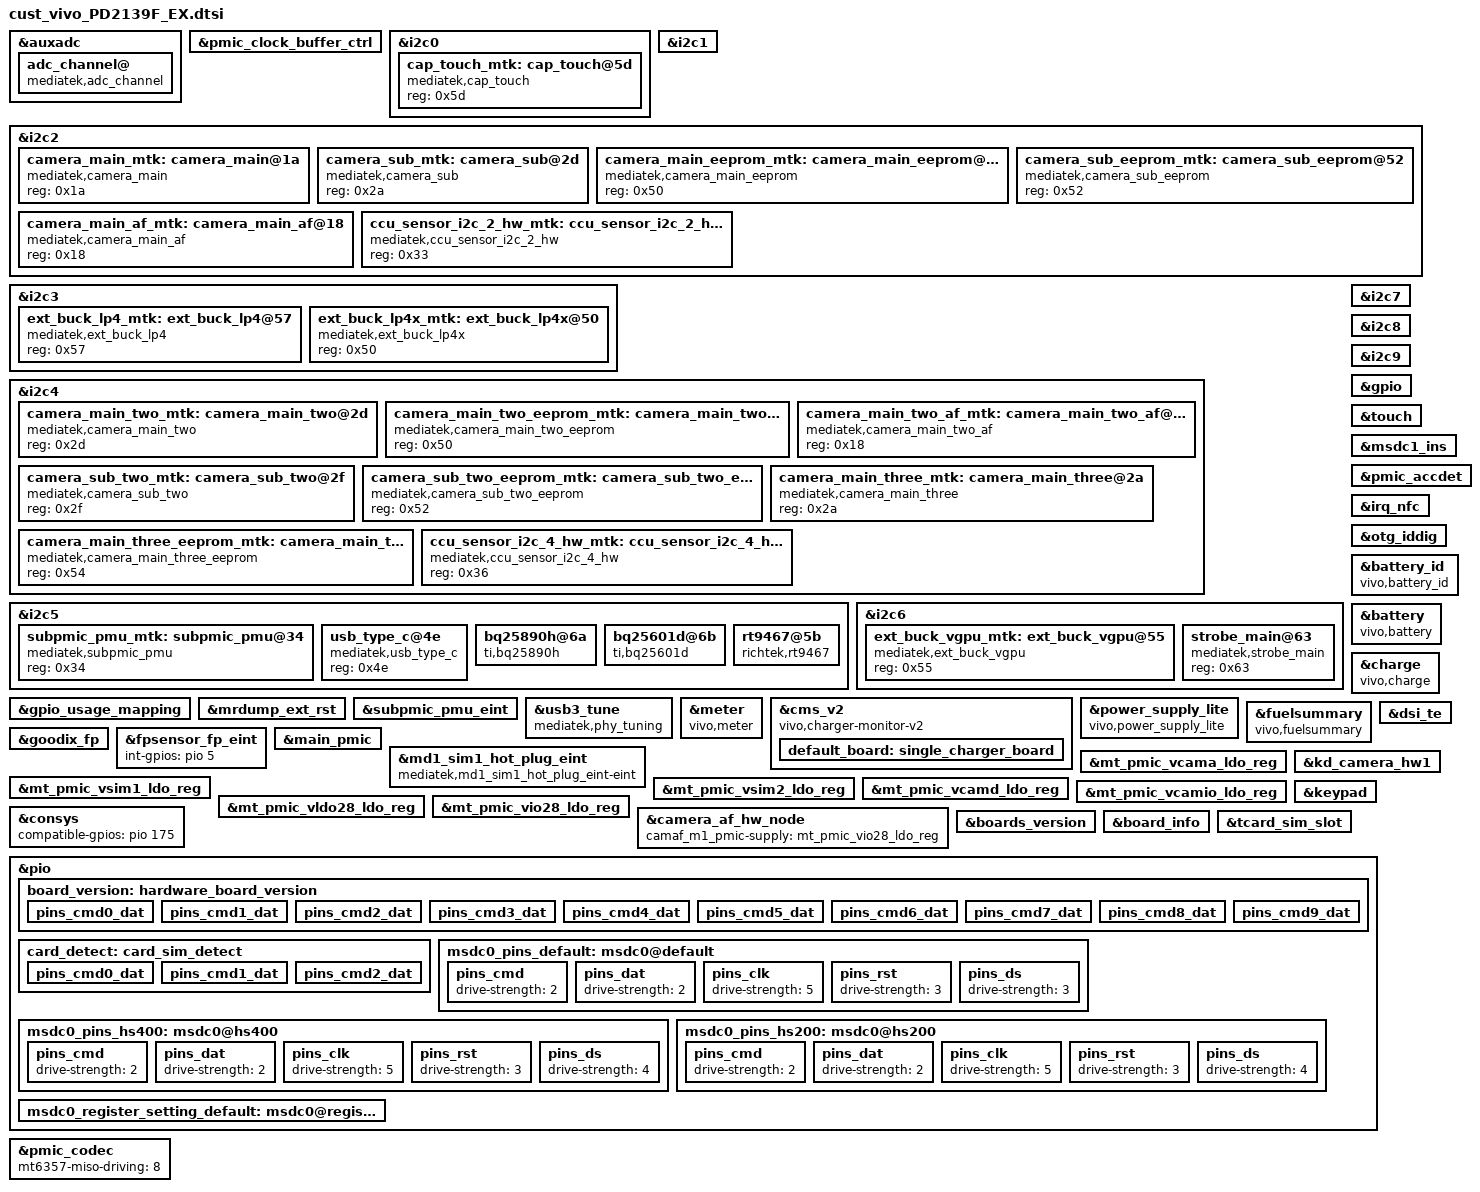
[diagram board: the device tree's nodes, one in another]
/*
 * Generated by MTK SP DrvGen Version: 3.5.160809 for MT6765.
 * 2018-01-30 14:59:45
 * Do Not Modify The File.
 * Copyright Mediatek Inc. (c) 2016.
*/

/*************************
 * ADC DTSI File
*************************/

&auxadc {
	adc_channel@ {
		compatible = "mediatek,adc_channel";
		mediatek,temperature0 = <0>;
		mediatek,temperature1 = <1>;
		mediatek,adc_fdd_rf_params_dynamic_custom_ch = <2>;
		status = "okay";
	};
};


/*************************
 * CLK_BUF DTSI File
*************************/

&pmic_clock_buffer_ctrl {
	mediatek,clkbuf-quantity = <7>;
	mediatek,clkbuf-config = <2 1 2 2 0 0 0>;
	mediatek,clkbuf-driving-current = <1 1 1 1 1 1 1>;
	status = "okay";
};


/*************************
 * I2C DTSI File
*************************/

&i2c0 {
	#address-cells = <1>;
	#size-cells = <0>;
	clock-frequency = <400000>;
	mediatek,use-open-drain;
	cap_touch_mtk:cap_touch@5d {
		compatible = "mediatek,cap_touch";
		reg = <0x5d>;
		status = "okay";
	};

};

&i2c1 {
	#address-cells = <1>;
	#size-cells = <0>;
	clock-frequency = <400000>;
	mediatek,use-open-drain;
};

&i2c2 {
	#address-cells = <1>;
	#size-cells = <0>;
	clock-frequency = <400000>;
	mediatek,use-open-drain;
	camera_main_mtk:camera_main@1a {
		compatible = "mediatek,camera_main";
		reg = <0x1a>;
		status = "okay";
	};

	camera_sub_mtk:camera_sub@2d {
		compatible = "mediatek,camera_sub";
		reg = <0x2a>;
		status = "okay";
	};

	camera_main_eeprom_mtk:camera_main_eeprom@50 {
		compatible = "mediatek,camera_main_eeprom";
		reg = <0x50>;
		status = "okay";
	};
        camera_sub_eeprom_mtk:camera_sub_eeprom@52 {
		compatible = "mediatek,camera_sub_eeprom";
		reg = <0x52>;
		status = "okay";
	};
	camera_main_af_mtk:camera_main_af@18 {
		compatible = "mediatek,camera_main_af";
		reg = <0x18>;
		status = "okay";
	};
	ccu_sensor_i2c_2_hw_mtk:ccu_sensor_i2c_2_hw@33 {
		compatible = "mediatek,ccu_sensor_i2c_2_hw";
		reg = <0x33>;
		status = "okay";
	};

};

&i2c3 {
	#address-cells = <1>;
	#size-cells = <0>;
	clock-frequency = <400000>;
	mediatek,use-open-drain;
	ext_buck_lp4_mtk:ext_buck_lp4@57 {
		compatible = "mediatek,ext_buck_lp4";
		reg = <0x57>;
		status = "okay";
	};

	ext_buck_lp4x_mtk:ext_buck_lp4x@50 {
		compatible = "mediatek,ext_buck_lp4x";
		reg = <0x50>;
		status = "okay";
	};

};

&i2c4 {
	#address-cells = <1>;
	#size-cells = <0>;
	clock-frequency = <400000>;
	mediatek,use-open-drain;
	camera_main_two_mtk:camera_main_two@2d {
		compatible = "mediatek,camera_main_two";
		reg = <0x2d>;
		status = "okay";
	};
	
	camera_main_two_eeprom_mtk:camera_main_two_eeprom@50 {
		compatible = "mediatek,camera_main_two_eeprom";
		reg = <0x50>;
		status = "okay";
	};

	camera_main_two_af_mtk:camera_main_two_af@18 {
		compatible = "mediatek,camera_main_two_af";
		reg = <0x18>;
		status = "okay";
	};
	camera_sub_two_mtk:camera_sub_two@2f {
		compatible = "mediatek,camera_sub_two";
		reg = <0x2f>;
		status = "okay";
	};
	camera_sub_two_eeprom_mtk:camera_sub_two_eeprom@52 {
		compatible = "mediatek,camera_sub_two_eeprom";
		reg = <0x52>;
		status = "okay";
	};
	camera_main_three_mtk:camera_main_three@2a {
		compatible = "mediatek,camera_main_three";
		reg = <0x2a>;
		status = "okay";
	};
	camera_main_three_eeprom_mtk:camera_main_three_eeprom@54 {
		compatible = "mediatek,camera_main_three_eeprom";
		reg = <0x54>;
		status = "okay";
	};
	ccu_sensor_i2c_4_hw_mtk:ccu_sensor_i2c_4_hw@36 {
		compatible = "mediatek,ccu_sensor_i2c_4_hw";
		reg = <0x36>;
		status = "okay";
	};
};

&i2c5 {
	#address-cells = <1>;
	#size-cells = <0>;
	clock-frequency = <400000>;
	mediatek,use-open-drain;
	subpmic_pmu_mtk:subpmic_pmu@34 {
		compatible = "mediatek,subpmic_pmu";
		reg = <0x34>;
		status = "okay";
	};
	usb_type_c@4e {
		compatible = "mediatek,usb_type_c";
		reg = <0x4e>;
		status = "okay";
	};
};

&i2c6 {
	#address-cells = <1>;
	#size-cells = <0>;
	clock-frequency = <400000>;
	mediatek,use-open-drain;

	ext_buck_vgpu_mtk:ext_buck_vgpu@55 {
		compatible = "mediatek,ext_buck_vgpu";
		reg = <0x55>;
		status = "okay";
	};

	/*hope add for flashlight i2c device start*/
	strobe_main@63 {
	        compatible = "mediatek,strobe_main";
	        reg = <0x63>;
	        status = "okay";
	};
	/*hope add for flashlight i2c device end*/

};

&i2c7 {
	#address-cells = <1>;
	#size-cells = <0>;
	clock-frequency = <400000>;
	mediatek,use-open-drain;
};

&i2c8 {
	#address-cells = <1>;
	#size-cells = <0>;
	clock-frequency = <400000>;
	mediatek,use-open-drain;
};

&i2c9 {
	#address-cells = <1>;
	#size-cells = <0>;
	clock-frequency = <400000>;
	mediatek,use-open-drain;
};



/*************************
 * GPIO DTSI File
*************************/

&gpio_usage_mapping {
	GPIO_SIM2_SIO = <&pio 35 0>;
	GPIO_SIM2_SRST = <&pio 36 0>;
	GPIO_SIM2_SCLK = <&pio 37 0>;
	GPIO_SIM1_SCLK = <&pio 38 0>;
	GPIO_SIM1_SRST = <&pio 39 0>;
	GPIO_SIM1_SIO = <&pio 40 0>;
	GPIO_SIM1_HOT_PLUG = <&pio 47 0>;
	GPIO_FDD_BAND_SUPPORT_DETECT_1ST_PIN = <&pio 176 0>;
	GPIO_FDD_BAND_SUPPORT_DETECT_2ND_PIN = <&pio 177 0>;
	GPIO_FDD_BAND_SUPPORT_DETECT_3RD_PIN = <&pio 178 0>;
	GPIO_FDD_BAND_SUPPORT_DETECT_4TH_PIN = <&pio 173 0>;
};

&gpio{
	gpio_init_default = <0 0 0 0 0 1 1>,
		<1 0 0 0 0 0 1>,
		<2 0 1 0 0 0 0>,//usb sel
		<3 0 0 0 1 1 1>,
		<4 0 0 0 1 1 0>,
		<5 0 0 0 1 0 0>,
		<6 0 0 0 1 1 0>,
		<7 0 0 0 1 1 0>,
		<8 0 0 0 0 0 1>,
		<9 0 0 0 0 0 0>,
		<10 0 1 0 1 1 1>,
		<11 0 0 0 0 0 0>,//main chg-int
		<12 0 0 0 1 0 0>,
		<13 3 0 0 1 0 0>,
		<14 3 1 0 0 0 0>,
		<15 3 1 0 0 0 0>,
		<16 3 1 0 0 0 0>,
		<17 2 0 0 1 0 0>,
		<18 2 0 0 1 0 0>,
		<19 2 0 0 0 0 0>,
		<20 2 0 0 1 0 0>,
		<21 0 1 0 0 0 0>,
		<22 0 0 0 1 0 0>,
		<23 0 0 0 0 0 0>,//sub chg-int
		<24 0 0 0 1 0 0>,
		<25 1 0 0 0 0 0>,
		<26 1 1 0 0 0 0>,
		<27 1 1 0 0 0 0>,
		<28 1 1 0 0 0 0>,
		<29 1 1 0 0 0 1>,
		<30 1 0 0 1 1 1>,
		<31 1 0 0 1 1 1>,
		<32 1 0 0 1 1 1>,
		<33 1 0 0 1 1 1>,
		<34 1 0 0 1 1 1>,
		<35 1 0 0 1 1 0>,
		<36 1 1 0 0 0 0>,
		<37 1 1 0 0 0 0>,
		<38 1 1 0 0 0 0>,
		<39 1 1 0 0 0 0>,
		<40 1 0 0 1 1 0>,
		<41 0 0 0 0 0 0>,
		<42 0 0 0 1 0 0>,
		<43 1 1 0 0 0 0>,
		<44 1 0 0 1 0 0>,
		<45 0 1 0 0 0 0>,
		<46 0 0 0 0 0 0>,
		<47 1 0 0 0 0 0>,
		<48 1 0 0 1 1 1>,
		<49 1 0 0 1 1 1>,
		<50 1 0 0 1 1 1>,
		<51 1 1 0 1 1 1>,
		<52 1 1 0 1 0 0>,
		<53 1 1 0 1 0 0>,
		<54 0 0 0 1 1 0>,
		<55 1 1 0 1 0 0>,
		<56 1 1 0 1 0 0>,
		<57 1 1 0 1 0 0>,
		<58 0 0 0 1 0 0>,
		<59 1 0 0 1 0 0>,
		<60 1 0 0 1 0 0>,
		<61 1 0 0 1 0 0>,
		<62 1 0 0 1 0 0>,
		<63 1 0 0 1 0 0>,
		<64 1 0 0 1 0 0>,
		<65 1 0 0 1 0 0>,
		<66 1 0 0 1 0 0>,
		<67 1 0 0 1 0 0>,
		<68 1 0 0 1 0 0>,
		<69 0 1 0 1 0 0>,//sub chg enable
		<70 1 1 0 1 0 0>,
		<71 1 1 0 1 0 0>,
		<72 1 1 0 1 0 0>,
		<73 0 1 0 1 0 0>,
		<74 0 1 0 1 0 0>,
		<75 0 0 0 1 0 0>,
		<76 1 1 0 1 0 0>,
		<77 1 1 0 1 0 0>,
		<78 0 0 0 1 1 0>,
		<79 0 0 0 1 0 0>,
		<80 0 0 0 1 0 0>,
		<81 1 0 0 1 1 1>,
		<82 1 0 0 1 1 1>,
		<83 1 0 0 1 1 1>,
		<84 1 0 0 1 1 1>,
		<85 1 1 0 1 0 0>,
		<86 1 1 0 1 0 0>,
		<87 0 1 0 0 0 0>,//CCM3_RST  front
		<88 0 0 0 1 0 0>,
		<89 1 0 0 1 0 0>,
		<90 0 0 0 1 0 0>,
		<91 0 1 0 1 0 0>,
		<92 0 0 0 1 0 0>,
		<93 1 0 0 1 1 0>,
		<94 0 0 0 1 0 0>,
		<95 1 0 0 1 1 0>,
		<96 1 1 0 0 0 0>,
		<97 0 1 0 0 0 0>,
		<98 0 1 0 0 0 0>,
		<99 0 1 0 0 0 0>,
		<100 0 1 0 0 0 0>,
		<101 0 1 0 0 0 0>,//ccm0_rst  rear main
		<102 0 1 0 0 0 0>,//cam2_rst  micro
		<103 1 0 0 0 0 1>,//iic2 scl
		<104 1 0 0 0 0 1>,//iic2 sda
		<105 1 0 0 0 0 1>,//iic4 scl
		<106 1 0 0 0 0 1>,//iic4 sda
		<107 0 0 0 1 1 0>,
		<108 0 1 0 0 0 0>,
		<109 0 1 0 0 0 0>,//CCM1_RST  boked
		<110 0 0 0 1 1 0>,//cc logic int-gpio
		<111 0 0 0 1 0 0>,
		<112 0 0 0 1 0 0>,
		<113 0 1 0 0 0 0>,
		<114 0 0 0 1 0 0>,
		<115 0 0 0 1 0 0>,
		<116 0 0 0 1 0 0>,
		<117 0 0 0 1 0 0>,
		<118 0 0 0 1 0 0>,
		<119 0 0 0 1 0 0>,
		<120 0 0 0 1 0 0>,
		<121 0 0 0 0 0 0>,
		<122 1 0 0 1 1 1>,
		<123 1 0 0 1 1 1>,
		<124 1 1 0 0 0 1>,
		<125 1 0 0 1 1 1>,
		<126 1 0 0 1 1 1>,
		<127 1 0 0 1 1 1>,
		<128 1 0 0 1 1 1>,
		<129 1 0 0 1 1 1>,
		<130 1 0 0 1 1 1>,
		<131 1 0 0 1 0 1>,
		<132 1 0 0 1 1 1>,
		<133 1 1 1 0 0 1>,
		<134 1 0 0 1 0 1>,
		<135 1 1 0 0 0 0>,
		<136 1 1 0 0 0 0>,
		<137 1 1 0 0 0 0>,
		<138 1 1 0 0 0 0>,
		<139 1 1 0 0 0 0>,
		<140 1 0 0 1 0 0>,
		<141 1 0 0 1 0 0>,
		<142 1 0 0 1 0 0>,
		<143 1 0 0 1 0 0>,
		<144 1 0 0 1 0 0>,
		<145 1 1 1 0 0 0>,
		<146 1 0 0 1 0 0>,
		<147 1 1 0 0 0 0>,
		<148 1 1 0 0 0 0>,
		<149 1 1 0 0 0 0>,
		<150 0 1 0 1 1 1>,
		<151 0 1 0 0 0 0>,
		<152 0 1 0 0 0 0>,
		<153 0 1 0 0 0 0>,
		<154 0 1 0 0 0 0>,
		<155 0 1 0 1 0 0>,
		<156 0 1 0 0 0 0>,
		<157 1 0 0 1 0 0>,
		<158 1 0 0 1 0 0>,
		<159 0 1 1 0 0 0>,
		<160 0 0 0 1 0 0>,
		<161 1 0 0 1 1 1>,
		<162 1 0 0 1 1 1>,
		<163 0 1 0 0 0 0>,//usb oe
		<164 0 0 0 0 0 0>,
		<165 0 0 0 0 0 0>,
		<166 0 1 0 1 0 0>,
		<167 0 0 0 1 0 0>,
		<168 0 0 0 1 0 0>,
		<169 0 1 0 0 0 0>,
		<170 0 1 0 0 0 0>,
		<171 0 0 0 1 1 0>,
		<172 0 1 1 0 0 0>,
		<173 0 0 0 1 1 0>,
		<174 0 0 0 1 1 0>,
		<175 0 0 0 1 1 0>,
		<176 0 0 0 1 1 0>,
		<177 0 0 0 1 1 0>,
		<178 0 0 0 1 1 0>,
		<179 0 0 0 1 0 0>;
};


/*************************
 * EINT DTSI File
*************************/

#include <dt-bindings/interrupt-controller/irq.h>
#include <dt-bindings/interrupt-controller/arm-gic.h>

&touch {
	interrupt-parent = <&pio>;
	interrupts = <0 IRQ_TYPE_EDGE_FALLING 0 0>;
	status = "okay";
};

&msdc1_ins {
	interrupt-parent = <&pio>;
	interrupts = <1 IRQ_TYPE_EDGE_FALLING 1 0>;
	status = "okay";
};

&mrdump_ext_rst {
	interrupt-parent = <&pio>;
	interrupts = <2 IRQ_TYPE_LEVEL_LOW 2 0>;
	deb-gpios = <&pio 2 0>;
	debounce = <512000>;
	status = "okay";
};

&pmic_accdet {
	interrupt-parent = <&pio>;
	interrupts = <4 IRQ_TYPE_LEVEL_LOW>,
				 <3 IRQ_TYPE_LEVEL_LOW>;
	deb-gpios = <&pio 4 0>;
	deb-rgpios = <&pio 3 0>;
	debounce = <256000>;
	debounce1 = <256000>;
	status = "okay";
};

&irq_nfc {
	interrupt-parent = <&pio>;
	interrupts = <10 IRQ_TYPE_LEVEL_HIGH 10 0>;
	status = "okay";
};

&subpmic_pmu_eint {
	interrupt-parent = <&pio>;
	interrupts = <11 IRQ_TYPE_EDGE_FALLING 11 0>;
	status = "okay";
};

&otg_iddig {
    interrupt-parent = <&pio>;
    interrupts = <110 IRQ_TYPE_LEVEL_LOW 110 0>;
    /*debounce = <110 0>;*/
    usbid-num = <&pio 110 1>;
	mtk,otg_chip_compatible_mode;
    usbid2-num = <&pio 167 1>;
    platform-id = <&pio 171 1>;
    pinctrl-names = "iddig_default", "iddig_otg_gpio", "iddig_otg_gpio_pull_down", "otg_gpio_pull_high", "otg_gpio_pull_low", "otg_gpio_pull_in", "otg_gpio_pull1_high", "otg_gpio_pull1_low", "otg_gpio_pull1_in", "iddig_otg_init", "otg_gpio167_pull_high", "otg_gpio167_pull_low", "otg_gpio167_pull_in";
    pinctrl-0 = <&iddig_default>;
    pinctrl-1 = <&gpio110_mode0_gpio>;
    pinctrl-2 = <&gpio110_mode0_gpio_pull_down>;
    pinctrl-3 = <&gpio165_otg_pull_high>;
    pinctrl-4 = <&gpio165_otg_pull_low>;
    pinctrl-5 = <&gpio165_otg_pull_in>;
    pinctrl-6 = <&gpio164_otg_pull1_high>;
    pinctrl-7 = <&gpio164_otg_pull1_low>;
    pinctrl-8 = <&gpio164_otg_pull1_in>;
    pinctrl-9 = <&gpio110_mode1_iddig>;
	
    pinctrl-10 = <&gpio167_otg_pull1_high>;
    pinctrl-11 = <&gpio167_otg_pull1_low>;
    pinctrl-12 = <&gpio167_otg_pull1_in>;
    status = "okay";
};

/*taozongchen add for usb start */
&usb3_tune {
	compatible = "mediatek,phy_tuning";
	u2_vrt_ref = <0x4>;
	u2_term_ref = <0x3>;
	u2_hstx_srctrl = <0x4>;
	u2_enhance = <0x3>;
	u2_vrt_ref_host = <0x4>;
	u2_term_ref_host = <0x5>;
	u2_hstx_srctrl_host = <0x4>;
	u2_enhance_host = <0x2>;

	board1_version_bit = <7>;
	board1_version_active = <0>;
	u2_vrt_ref1 = <0x4>;
	u2_term_ref1 = <0x3>;
	u2_hstx_srctrl1 = <0x4>;
	u2_enhance1 = <0x3>;
	u2_vrt_ref_host1 = <0x4>;
	u2_term_ref_host1 = <0x2>;
	u2_hstx_srctrl_host1 = <0x4>;
	u2_enhance_host1 = <0x2>;
	status = "okay";
};
/* taozongchen add for usb end */

/* fuxi add for battery&charge start */
&battery_id {
	status = "okay";
	compatible = "vivo,battery_id";

	vivo,bat-adc-ctrl-gpio = <&pio 159 0>;

	io-channels = <&auxadc 3>;
	io-channel-names = "battery_id_adc";

	vivo,bat-name = "B-S2 ATL 5000","B-S1 LW 5000","B-S2 ATL 5000","B-S3 ATL 5000","UNKNOWN";
};

&battery {
	status = "okay";
	compatible = "vivo,battery";

	io-channels = <&auxadc 0>,
		<&auxadc 1>,
		<&auxadc 2>;
	io-channel-names = "primary_board_therm",
		"pa_therm",
		"parallel_board_therm";

	vivo,low-volt-threshold = <3400>;
	vivo,soft-rise-percent = <96>;
	vivo,soft-rise-cumulative = <3>;
	vivo,soft-rise-keep-cumulative = <10>;
	vivo,percnet-sync-delta = <8>;
	vivo,percnet-sync-cumulative = <9>;
	vivo,full-sync-cumulative = <3>;
	vivo,soft-term-percent = <99>;
	vivo,soft-term-cumulative = <30>;
};

&charge {
	status = "okay";
	compatible = "vivo,charge";

	vivo,chg-wdt-s = <40>;
	vivo,re-chg-voltage-mv = <100>;
	vivo,prechg-voltage-mv = <3000>;
	vivo,iprechg-current-ma = <300>;
	vivo,iterm-current-ma = <256>;
	vivo,vreg-voltage-mv = <4430>;
	vivo,vindpm-voltage-mv = <4500>;
	vivo,sys-voltage-min-mv= <3300>;
	vivo,boostv-voltage-mv = <5150>;
	vivo,boostv-ilimit-ma = <1300>;
	vivo,ovp-voltage-mv = <14000>;

	/*
	 * 0  auto detect charging
	 * 1  vivo-normal chargine
	 * 2  vivo-single engine charging
	 * 3  vivo-dual engine charging
	 * 4  vivo-flash charging
	*/
	vivo,charge-scheme = <0>;
	vivo,direct-charger-enable;

	/*
	 * SUPPORTED_ADAPTER_DEFAULT = 0,
	 * SUPPORTED_ADAPTER_VIVO_LV_DCHG_5V_4500MA = 1,
	 * SUPPORTED_ADAPTER_VIVO_HV_DCHG_10V_2250MA = 2,
	 * SUPPORTED_ADAPTER_QC20__9V_2000MA = 3,
	 * SUPPORTED_ADAPTER_VIVO_HV_DCHG_10V_4000MA = 4,
	 * SUPPORTED_ADAPTER_MAX,
	 */
	vivo,supported-adapter = <3>;

	//parameter for 9V2A
	vivo,primary-ichg-max-ma = <2240>;
	vivo,parallel-ichg-max-ma = <1680>;

	vivo,flashchg-spec-ma = <2000 3300 6000>;
	vivo,fastchg-spec-ma = <2000 2100 3800>;
	vivo,normalchg-spec-ma = <2000 1500 2300>;

	/* 0---PMIC; 1---CHGIC */
	vivo,vbus-detect-source = <0>;

	vivo,usboe-gpio = <&pio 163 0>;
	vivo,usbsel-gpio = <&pio 2 0>;

	/*ffc*/
	//vivo,ffc-enable;
	vivo,ffc-iterm-ma = <(-750)>;
	vivo,ffc-vreg-mv = <4500>;
	vivo,ffc-temperature-range = <150 450>;
	vivo,ffc-full-vbat-table-size = <3>;
	vivo,ffc-full-vbat-table = <4480 4490 4460>;
	vivo,ffc-full-ibat-table-size = <2>;
	vivo,ffc-full-ibat-table = <150 349 (-980)>,
		<350 449 (-1176)>;
};

&meter {
	status = "okay";
	compatible = "vivo,meter";

	vivo,load-capacity-delta-max = <60>;
	vivo,poweron-delta-capacity = <20>;
	vivo,poweron-low-capacity = <3>;
	vivo,volt-car-delta = <10>;
	vivo,car-volt-delta = <8>;
	vivo,meter-res-compesate = <10>;
	vivo,ocv-board-compesate = <0>;

	/* 0---AGING_UNSUPPORTED; 1---DRIVER_SUPPORTED; 2---USPACE_SUPPORTED */
	vivo,battery-aging-support = <2>;

	vivo,capacity-mAh = <4910>;
	/*COLD_CHG COLD_DISCHG NORMAL_CHG NORMAL_DISCHG*/
	vivo,car-tune-value = <1000 1005 1010 1000>,
		<1030 1005 1010 1000>,
		<1000 1005 1010 1000>,
		<1010 1000 1010 1000>,
		<1000 1000 1000 1000>,
		<1000 1000 1000 1000>;
	vivo,bats-qmax = <4260 4300 4616 4860 4870>,
		<3200 3850 4400 4590 4660>,
		<4260 4300 4616 4860 4870>,
		<3900 4181 4505 4548 4590>,
		<4500 4668 4762 4851 4821>,
		<4500 4668 4762 4851 4821>;

	/* car-tune adjust remap */
	vivo,car-tune-adjust-enable;
	vivo,car-tune-adjust-size = <3>;
	vivo,car-tune-adjust-table = <0 10 (330) 7>,
		<11 20 (-30) 8>,
		<21 100 (-30) 12>;

	#include "bat_setting/vivo_battery_table_pd2139.dtsi"
};

&cms_v2 {
	compatible = "vivo,charger-monitor-v2";
	status = "okay";

	default_board: single_charger_board {
		/*default board: keep in xxxxxx*/
		support-board-version = "xxxxxx";

		vivo,bat-det-method = <0>;//r:0, rc:1, eprom:2, ex-fg:3
		vivo,bat-id-gpio = <&pio 159 0>;
		
		/*
		CHG0__CHARGING_TECHNOLOGY_NONE = 0,
		CHG1__NORMAL_CHARGING,			//5V/2A normal charging
		CHG2__QC2_CHARGING,				//9V/2A	QC2.0 charging
		CHG3__LOW_VOLTAGE_DIRECT_CHARGING,		//5V/4.5A direct charging
		CHG4__SINGLE_IC_DIV2_CHARGING,		//single IC Div/2 charging
		CHG5__DUAL_IC_DIV2_CHARGING,			//Dual IC Div/2 charging
		CHG6__DUAL_IC_DUAL_BATTERY_DIV2_CHARGING,	//Dual IC Div/2 charging
		CHGX__CHARGING_TECHNOLOGY_MAX,
		*/
		vivo,charging-technology = <2>;
		//vivo,no-bat-warning;
		//vivo,no-chg-timeout;
		vivo,chg-timeout-mins = <900>;

		//high temperature charger current control enable
		vivo,htccc-enable;
		vivo,htccc-data = <46 55 4100000 100000>;

		//vivo,fbon-scale-enable;/*disable default*/
		vivo,fbon-scale-data = <2 100 100>;

		//vivo,switch-scale-enable;/*disable from rom4.0*/
		vivo,switch-scale-data = <75 53>;

		vivo,calling-scale-enable;
		vivo,calling-scale-data = <100 21>;/*ibat:3900 * 0.54 = 2106,more than 1500,not exit dchg*/
		vivo,calling-dchg-disable;

		vivo,weixin-calling-scale-enable;
		vivo,weixin-calling-scale-data = <100 112>;/*5000mA*/

		//vivo,fixed-scale-enable;
		vivo,fixed-scale-data = <120 3800 0>;/*dchg fixed time adjust the max ibat,disable default*/

		/*data processing : batt-temp*/
		vivo,dp-batt-temp-enable;
		vivo,dp-batt-temp-data = <100>;

		/* charging current for devices in exhibition mode */
		vivo,exhibition-mode-current-primary = <2048>;
		vivo,exhibition-mode-current-parallel = <0>;

		       /*default tc parameter*/
		       //single charger ibat scale base on temperature battery cell info:1C/1.2C 3960mah
		       /* tmin, tmax, data, volt1, data_ex1, volt2, data_ex2. */
		       vivo,normal-tc-row-col = <10 9>;
		       vivo,normal-tc-data = <550 8888 0 0 0 0 0 0 0>,
			       <450 549 50 0 0 0 0 0 0>,
			       <200 449 100 4200000 70 0 0 0 0>,
			       <150 199 100 4200000 70 0 0 0 0>,
			       <100 149 70 4200000 50 0 0 0 0>,
			       <50 99 50 4200000 30 0 0 0 0>,
			       <0 49 50 4200000 30 0 0 0 0>,
			       <(-8888) (-1) 0 0 0 0 0 0 0>,
			       <(-8888) (-1) 0 0 0 0 0 0 0>,
			       <(-8888) (-1) 0 0 0 0 0 0 0>;

		       /*flash tc parameter*/
		       vivo,flash-normal-tc-row-col = <10 9>;
		       vivo,flash-normal-tc-data = <550 8888 0 0 0 0 0 0 0>,
			       <450 549 50 0 0 0 0 0 0>,
			       <350 449 123 4430000 87 0 0 0 0>,
			       <200 349 123 4430000 87 0 0 0 0>,
			       <150 199 123 4300000 102 4430000 80 0 0>,
			       <100 149 100 0 0 0 0 0 0>,
			       <50 99 70 4200000 50 0 0 0 0>,
			       <0 49 70 4200000 50 0 0 0 0>,
			       <(-50) (-1) 0 0 0 0 0 0 0>,
			       <(-8888) (-51) 0 0 0 0 0 0 0>;

		/*adjust fastchg base on board temperature and fb off*/
		vivo,intell-charge-enable;
		vivo,parallel-temp-enable = <1 1>;//<x y> x:fb-on y:fb-off

		/* Flash charge fb-on intell param */
		vivo,primary-fbon-tc-row-col = <6 3>;
		vivo,primary-fbon-tc-data = <460 8888 1600>,
			<410 459 2600>,
			<400 409 3000>,
			<390 399 3300>,
			<371 389 3700>,
			<(-8888) 370 6000>;

		vivo,parallel-fbon-tc-row-col = <1 3>;
		vivo,parallel-fbon-tc-data = <(-8888) 8888 0>;

		/* Flash charge fb-off intell param */
		vivo,primary-fboff-tc-row-col = <6 3>;
		vivo,primary-fboff-tc-data = <450 8888 1800>,
			<390 449 3000>,
			<380 389 3400>,
			<376 379 3700>,
			<371 375 4100>,
			<(-8888) 370 6000>;
		vivo,parallel-fboff-tc-row-col = <1 3>;
		vivo,parallel-fboff-tc-data = <(-8888) 8888 0>;

		/* 9v Fast charge fb-on intell param */
		vivo,9v-primary-fbon-tc-row-col = <7 3>;
		vivo,9v-primary-fbon-tc-data = <490 8888 500>,
			<470 489 500>,
			<450 469 900>,
			<435 449 1040>,
			<410 434 1200>,
			<380 409 1300>,
			<(-8888) 379 1500>;
		vivo,9v-parallel-fbon-tc-row-col = <6 3>;
		vivo,9v-parallel-fbon-tc-data = <460 8888 500>,
			<440 459 850>,
			<420 439 1060>,
			<400 419 1150>,
			<380 399 1300>,
			<(-8888) 379 1500>;
		// second parallel parameter, for rt9467
		vivo,9v-2nd-parallel-fbon-tc-row-col = <3 3>;
		vivo,9v-2nd-parallel-fbon-tc-data = <401 8888 512>,
			<386 400 800>,
			<(-8888) 385 1000>;


		/* 9v Fast charge fb-off intell param */
		vivo,9v-primary-fboff-tc-row-col = <7 3>;
		vivo,9v-primary-fboff-tc-data = <436 8888 300>,
			<426 435 500>,
			<401 425 1300>,
			<386 400 1500>,
			<371 385 1700>,
			<361 370 1850>,
			<(-8888) 360 2000>;
		vivo,9v-parallel-fboff-tc-row-col = <7 3>;
		vivo,9v-parallel-fboff-tc-data = <436 8888 0>,
			<426 435 500>,
			<401 425 1000>,
			<386 400 1200>,
			<371 385 1400>,
			<361 370 1500>,
			<(-8888) 360 1600>;
		// second parallel parameter, for rt9467
		vivo,9v-2nd-parallel-fboff-tc-row-col = <6 3>;
		vivo,9v-2nd-parallel-fboff-tc-data = <431 8888 500>,
			<411 430 700>,
			<381 410 790>,
			<371 380 1050>,
			<351 370 1300>,
			<(-8888) 350 1500>;


		/* 5v Normal charge fb-on intell param */
		vivo,5v-primary-fbon-tc-row-col = <7 3>;
		vivo,5v-primary-fbon-tc-data = <491 8888 512>,
			<471 490 1024>,
			<451 470 1300>,
			<441 450 1500>,
			<421 440 1650>,
			<381 420 1800>,
			<(-8888) 380 2048>;
		vivo,5v-parallel-fbon-tc-row-col = <1 3>;
		vivo,5v-parallel-fbon-tc-data = <(-8888) 8888 0>;

		/* 5v Normal charge fb-off intell param */
		vivo,5v-primary-fboff-tc-row-col = <5 3>;
		vivo,5v-primary-fboff-tc-data = <431 8888 300>,
			<421 430 500>,
			<411 420 1000>,
			<401 410 1500>,
			<(-8888) 400 2000>;
		vivo,5v-parallel-fboff-tc-row-col = <1 3>;
		vivo,5v-parallel-fboff-tc-data = <(-8888) 8888 0>;

		// Direct charging param
		vivo,direct-charger-enable;//porting_check
		vivo,ex-bms-psy-name = "bq_bms";

		// bat_baord, usb_conn, pcb_conn(master_bat_conn), bat_conn
		vivo,dchg-ntc-protect-enable;
		vivo,dchg-ntc-protect-data = <750 800 850 850>;

		vivo,adapter-cooldown-data = <900 850 3400>;
		/*adapter power derate*/
		vivo,adapter-power-derate-enable;

		/* usb connecter protect param
		 * USB_PROTECT_NONE = 0,
		 * USB_CONN_TEMP_HEAT_PROTECT = BIT(0),
		 * USB_ID_PROTECT = BIT(1),
		 */
		vivo,usb-connecter-protect-enable = <1>;
		vivo,usb-id-protect-data= <1100 1547 500>;/* 500K, 2M, fcc */
		vivo,usb-conn-heat-protect-data-row-col = <2 4>;
		vivo,usb-conn-heat-protect-data= <260 8888 670 620>,
			<(-8888) 259 570 520>;

		/*
		 * max vbus of adapter:11v, max ibus of adapter:5A
		 * min voltage of battery for half chg:3500mV,max voltage of battery for half charge:4100mV,
		 * 5V2A charge min current threshold: 1000mA,5V2A charge max current threshold:2100mA,
		 * flash charge min current threshold:5000mA,flash charge max current threshold:11000mA
		 */

		/*default parameter*/
		vivo,charge-param-judge-threshold = <9 2 3500 4300 1000 2100 2100 4600>;
		/* factory mode charging test param */
		vivo,charge-test-param-row-col = <12 3>;
		vivo,charge-test-param-data = <0 0 5500>, /* cable resistance, min value, max value */
		        <0 0 5500>, /* master ibus, min ibus, max ibus */
		        <0 0 5500>, /* slave ibus, min ibus, max ibus */
		        <1 20 40>, /* batt therm ntc, min value, max value */
		        <1 20 45>, /* board therm ntc, min value, max value */
		        <0 20 50>, /* sub charger ntc, min value, max value */
		        <0 20 45>, /* usb con ntc, min value, max value */
		        <0 20 45>, /* usb con 1 ntc, double usb NTC, min value, max value */
		        <0 20 45>, /* bat btb master ntc, min value, max value */
		        <0 20 50>, /* bat btb sub ntc, min value, max value */
		        <0 20 50>, /* bat board ntc, min value, max value */
		        <0 20 50>; /* wireless charge coil ntc, min value, max value */

		/*flash parameter*/
		vivo,flash-charge-param-judge-threshold = <11 3 3500 4100 1000 2200 4000 6100>;
		/* factory mode charging test param */
		vivo,flash-charge-test-param-row-col = <12 3>;
		vivo,flash-charge-test-param-data = <1 0 5500>, /* cable resistance, min value, max value */
		        <1 0 5500>, /* master ibus, min ibus, max ibus */
		        <0 0 5500>, /* slave ibus, min ibus, max ibus */
		        <1 20 40>, /* batt therm ntc, min value, max value */
		        <1 20 45>, /* board therm ntc, min value, max value */
		        <0 20 50>, /* sub charger ntc, min value, max value */
		        <1 20 45>, /* usb con ntc, min value, max value */
		        <0 20 45>, /* usb con 1 ntc, double usb NTC, min value, max value */
		        <1 20 45>, /* bat btb master ntc, min value, max value */
		        <0 20 50>, /* bat btb sub ntc, min value, max value */
		        <0 20 50>, /* bat board ntc, min value, max value */
		        <0 20 50>; /* wireless charge coil ntc, min value, max value */
		#include "bat_setting/PD2139_battery_chg_params.dtsi"
	};
};


&power_supply_lite {
	status = "okay";
	compatible = "vivo,power_supply_lite";
};

&fuelsummary {
	status = "okay";
	compatible = "vivo,fuelsummary";

	/************************************************************
	 *
	 *  0   vivo-fastchg
	 *  1   qcom-dualchg
	 *  2   mtk-dualchg
	 *  3   qcom-normchg
	 *  4   mtk-normchg
	 *
	 ***********************************************************/
	chg-scheme = <2>;
	fex-version = <3>;
	fbon-ibat = <(-900)>;
	fboff-ibat = <(-1000)>;

	/* 0---AGING_UNSUPPORTED; 1---DRIVER_SUPPORTED; 2---USPACE_SUPPORTED */
	vivo,battery-aging-support = <2>;
};

&i2c5 {
	#address-cells = <1>;
	#size-cells = <0>;
	status = "okay";
	clock-frequency = <100000>;
	bq25890h@6a {
		compatible = "ti,bq25890h";
		reg = <0x6a>;

		vivo,int-gpio = <&pio 11 0>;
	};

	bq25601d@6b {
		compatible = "ti,bq25601d";
		reg = <0x6b>;

		vivo,int-gpio = <&pio 23 0>;
		vivo,enable-gpio = <&pio 69 0>;
	};

	rt9467@5b {
		compatible = "richtek,rt9467";
		reg = <0x5b>;

		vivo,int-gpio = <&pio 11 0>;
		//vivo,enable-gpio = <&pio 187 0>;
	};

};
/* fuxi add for battery&charge end */

&goodix_fp {
	interrupt-parent = <&pio>;
	interrupts = <5 IRQ_TYPE_EDGE_RISING 5 0>;
	vfp-supply = <&mt_pmic_vcama_ldo_reg>;
	fpc,enable-wakeup;
	status = "okay";
};

&fpsensor_fp_eint{
	int-gpios = <&pio 5 0x0>;
};

&dsi_te {
	interrupt-parent = <&pio>;
	interrupts = <44 IRQ_TYPE_EDGE_RISING 44 1>;
	status = "okay";
};

&main_pmic {
	interrupt-parent = <&pio>;
	interrupts = <144 IRQ_TYPE_LEVEL_HIGH 144 1>;
	status = "okay";
};



/*************************
 * MD1_EINT DTSI File
*************************/

&md1_sim1_hot_plug_eint {
	compatible = "mediatek,md1_sim1_hot_plug_eint-eint";
	interrupts = <0 8>;
	debounce = <0 100000>;
	dedicated = <0 0>;
	src_pin = <0 1>;
	sockettype = <0 0>;
	status = "okay";
};



/*************************
 * PMIC DTSI File
*************************/

&mt_pmic_vcama_ldo_reg {
	regulator-name = "vcama";
	regulator-default-on = <1>; /* 0:skip, 1: off, 2:on */
	status = "okay";
};
&mt_pmic_vsim1_ldo_reg {
	regulator-name = "vsim1";
	regulator-default-on = <1>; /* 0:skip, 1: off, 2:on */
	status = "okay";
};
&mt_pmic_vsim2_ldo_reg {
	regulator-name = "vsim2";
	regulator-default-on = <1>; /* 0:skip, 1: off, 2:on */
	status = "okay";
};
&mt_pmic_vcamd_ldo_reg {
	regulator-name = "vcamd";
	regulator-default-on = <1>; /* 0:skip, 1: off, 2:on */
	status = "okay";
};
&mt_pmic_vcamio_ldo_reg {
	regulator-name = "vcamio";
	regulator-default-on = <1>; /* 0:skip, 1: off, 2:on */
	status = "okay";
};
&mt_pmic_vldo28_ldo_reg {
	regulator-name = "vldo28";
	regulator-min-microvolt = <3000000>;
	regulator-max-microvolt = <3000000>;
	regulator-default-on = <2>; /* 0:skip, 1: off, 2:on */
	status = "okay";
};
&mt_pmic_vio28_ldo_reg {
	regulator-name = "vio28";
	regulator-default-on = <1>; /* 0:skip, 1: off, 2:on */
	status = "okay";
};

&kd_camera_hw1 {
	cam0_vcamio-supply = <&mt_pmic_vcamio_ldo_reg>;
	cam0_vcamd-supply = <&mt_pmic_vcamd_ldo_reg>;
	
	cam1_vcamio-supply= <&mt_pmic_vcamio_ldo_reg>;

	cam2_vcamio-supply= <&mt_pmic_vcamio_ldo_reg>;
	
	cam3_vcamio-supply= <&mt_pmic_vcamio_ldo_reg>;
	
	cam0_enable_sensor = "s5kjn1sq03pd2139_mipi_raw ov13b10pd2139_mipi_raw ov13b102apd2139_mipi_raw";
	cam1_enable_sensor = "imx355pd2139_mipi_raw imx355v1pd2139_mipi_raw gc08a3pd2139_mipi_raw";
	cam2_enable_sensor = "gc02m1pd2139_mipi_raw gc02m1bpd2139_mipi_mono";
	cam3_enable_sensor = "gc02m1pd2139_mipi_raw";
	
	status = "okay";
};

/*hope add main af pmic power start*/
&camera_af_hw_node {
	camaf_m1_pmic-supply = <&mt_pmic_vio28_ldo_reg>;
};
/*hope add main af pmic power end*/

/*hope add flashlight lm3644 for flash irq start */
/*
&flashlights_lm3644 {
	interrupt-parent = <&pio>;
	interrupts = <107 IRQ_TYPE_EDGE_RISING 107 0>;
	deb-gpios = <&pio 107 0>;
	debounce = <256000>;
	status = "okay";
};
*/
/*hope add flashlight lm3644 for flash irq end */

/*
&touch {
	vtouch-supply = <&mt_pmic_vldo28_ldo_reg>;
	status = "okay";
};
*/

/*************************
 * POWER DTSI File
*************************/



/*************************
 * KPD DTSI File
*************************/

&keypad {
	mediatek,kpd-key-debounce = <1024>;
	mediatek,kpd-sw-pwrkey = <116>;
	mediatek,kpd-hw-pwrkey = <8>;
	mediatek,kpd-sw-rstkey  = <114>;
	mediatek,kpd-hw-rstkey = <17>;
	mediatek,kpd-use-extend-type = <0>;
	/*HW Keycode [0~71] -> Linux Keycode*/
	mediatek,kpd-hw-map-num = <72>;
	mediatek,kpd-hw-init-map = <115 0 0 0 0 0 0 0 0 0 0 0 0 0 0 0 0 0 0 0 0 0 0 0 0 0 0 0 0 0 0 0 0 0 0 0 0 0 0 0 0 0 0 0 0 0 0 0 0 0 0 0 0 0 0 0 0 0 0 0 0 0 0 0 0 0 0 0 0 0 0 0 >;
	mediatek,kpd-pwrkey-eint-gpio = <0>;
	mediatek,kpd-pwkey-gpio-din  = <0>;
	mediatek,kpd-hw-dl-key0 = <17>;
	mediatek,kpd-hw-dl-key1 = <0>;
	mediatek,kpd-hw-dl-key2 = <8>;
	mediatek,kpd-hw-recovery-key = <17>;
	mediatek,kpd-hw-factory-key = <0>;
	status = "okay";
};

/*************************
 * wifi related
 * wifi_vcn33_ldo_removed means this project has no LDO
 * wifi_need_param_compatible means this project need param compatible
*************************/
/*
&vivo_wifi {
    mediatek,wifi_vcn33_ldo_removed;
    mediatek,wifi_need_param_compatible;
};
*/
/*************************
 * wifi compatible for WIFI filter
 * NC -- 1 -- first
 * 1K -- 0 -- second
*************************/
&consys {
    compatible-gpios = <&pio 175 0>;
};

/* pcb verison maps */
/* gpio 54 78 : 00 -> MP_0.1 */
/* gpio 54 78 : 01 -> MP_0.2 */
/* gpio 54 78 : 10 -> MP_0.3 */
/* gpio 54 78 : 11 -> MP_0.4 */
&boards_version {
	pinctrl-names = "default";
	pinctrl-0 = <&board_version>;
	gpio_nums = <10>;
	gpios = <178 177 176 175 174 173 171 7 164 24>;
	gpios_start = <&pio 7 0>;
	pcb_gpio_nums = <2>;
	pcb_gpios = <54 78>;
	pcb_gpios_start = <&pio 54 0>;
	/*0x0:MP_0.1, 0x1:MP_0.2, 0x2:MP_0.3, 0x3:MP_0.4,*/
	pcb_gpios_maps = <0x0 0x1 0x1 0x2 0x2 0x3 0x3 0x4>;
};

&board_info {
	vivo,vendor_project_name = "PD2139F_EX";
	vivo,vendor_project_cpu = "MT6765";
	vivo,vendor_project_freq = "2.3";
	vivo,vendor_project_cpunum = <8>;
};

&tcard_sim_slot {	
		pinctrl-names = "default";
		pinctrl-0 = <&card_detect>;
        factory-test,sim1-card;
        factory-test,sim2-card;
		factory-test,tf-card;
		vivo,new_card_detect;
        card-detect-sim1,gpios = <&pio 47 0x0>;
        card-detect-sim2,gpios = <&pio 47 0x0>;
		card-detect-tf-card,gpios = <&pio 1 0x0>;	
};

&pio {
	board_version: hardware_board_version {		
		pins_cmd0_dat {
			pinmux = <PINMUX_GPIO178__FUNC_GPIO178>;
			slew-rate = <0>;
			bias-pull-up = <1>;
		};
		pins_cmd1_dat {
			pinmux = <PINMUX_GPIO177__FUNC_GPIO177>;
			slew-rate = <0>;
			bias-pull-up = <1>;
		};
		pins_cmd2_dat {
			pinmux = <PINMUX_GPIO176__FUNC_GPIO176>;
			slew-rate = <0>;
			bias-pull-up = <1>;
		};	
		pins_cmd3_dat {
			pinmux = <PINMUX_GPIO175__FUNC_GPIO175>;
			slew-rate = <0>;
			bias-pull-up = <1>;
		};	
		pins_cmd4_dat {
			pinmux = <PINMUX_GPIO174__FUNC_GPIO174>;
			slew-rate = <0>;
			bias-pull-up = <1>;
		};
		pins_cmd5_dat {
			pinmux = <PINMUX_GPIO173__FUNC_GPIO173>;
			slew-rate = <0>;
			bias-pull-up = <1>;
		};
		pins_cmd6_dat {
			pinmux = <PINMUX_GPIO171__FUNC_GPIO171>;
			slew-rate = <0>;
			bias-pull-up = <1>;
		};
		pins_cmd7_dat {
			pinmux = <PINMUX_GPIO7__FUNC_GPIO7>;
			slew-rate = <0>;
			bias-pull-up = <1>;
		};
		pins_cmd8_dat {
			pinmux = <PINMUX_GPIO164__FUNC_GPIO164>;
			slew-rate = <0>;
			bias-pull-up = <1>;
		};
		pins_cmd9_dat {
			pinmux = <PINMUX_GPIO24__FUNC_GPIO24>;
			slew-rate = <0>;
			bias-pull-up = <1>;
		};
	};
	
	card_detect: card_sim_detect {
		pins_cmd0_dat {
			pinmux = <PINMUX_GPIO47__FUNC_MD_INT1_C2K_UIM0_HOT_PLUG>;
			slew-rate = <0>;
			bias-disable;
		};
		pins_cmd1_dat {
			pinmux = <PINMUX_GPIO46__FUNC_GPIO46>;
			slew-rate = <0>;
			bias-disable;
		};		
		pins_cmd2_dat {
			pinmux = <PINMUX_GPIO1__FUNC_GPIO1>;
			slew-rate = <0>;
			bias-disable;
		};
	};
};

/*add for mmc driver streng*/
&pio {
	msdc0_pins_default: msdc0@default {
		pins_cmd {
			drive-strength = /bits/ 8 <2>;
		};
		pins_dat {
			drive-strength = /bits/ 8 <2>;
		};
		pins_clk {
			drive-strength = /bits/ 8 <5>;
		};
		pins_rst {
			drive-strength = /bits/ 8 <3>;
		};
		pins_ds {
			drive-strength = /bits/ 8 <3>;
		};
	};

	msdc0_pins_hs400: msdc0@hs400 {
		pins_cmd {
			drive-strength = /bits/ 8 <2>;
		};
		pins_dat {
			drive-strength = /bits/ 8 <2>;
		};
		pins_clk {
			drive-strength = /bits/ 8 <5>;
		};
		pins_rst {
			drive-strength = /bits/ 8 <3>;
		};
		pins_ds {
			drive-strength = /bits/ 8 <4>;
		};
	};

	msdc0_pins_hs200: msdc0@hs200 {
		pins_cmd {
			drive-strength = /bits/ 8 <2>;
		};
		pins_dat {
			drive-strength = /bits/ 8 <2>;
		};
		pins_clk {
			drive-strength = /bits/ 8 <5>;
		};
		pins_rst {
			drive-strength = /bits/ 8 <3>;
		};
		pins_ds {
			drive-strength = /bits/ 8 <4>;
		};
	};

	msdc0_register_setting_default: msdc0@register_default {
		cmd_edge = /bits/ 8 <MSDC_SMPL_RISING>;
		rdata_edge = /bits/ 8 <MSDC_SMPL_RISING>;
		wdata_edge = /bits/ 8 <MSDC_SMPL_RISING>;
	};
};

&pmic_codec {
	mt6357-miso-driving = <8>;
};
